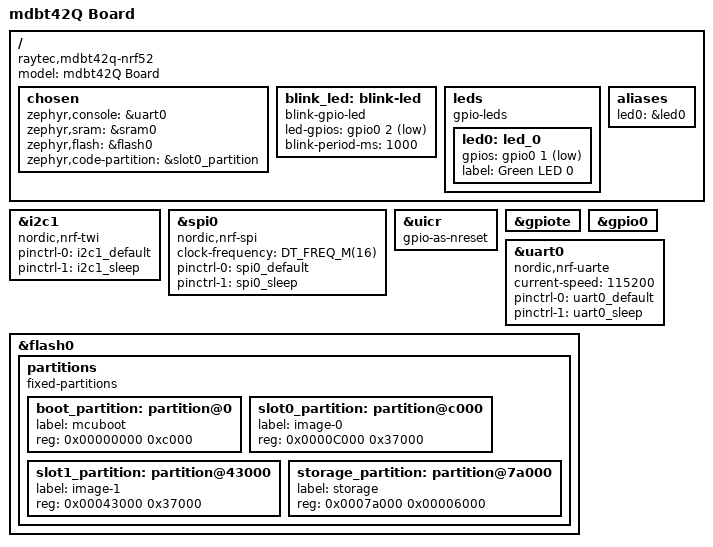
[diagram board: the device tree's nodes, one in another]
/*
 * Copyright (c) 2021 Nordic Semiconductor ASA
 * SPDX-License-Identifier: Apache-2.0
 */

/dts-v1/;
#include <nordic/nrf52832_qfaa.dtsi>
#include "mdbt42q_nrf52-pinctrl.dtsi"
#include <zephyr/dt-bindings/input/input-event-codes.h>

/ {
	model = "mdbt42Q Board";
	compatible = "raytec,mdbt42q-nrf52";

	chosen {
		zephyr,console = &uart0;
		// zephyr,sram = &sram0;
		// zephyr,flash = &flash0;
		zephyr,sram = &sram0;
		zephyr,flash = &flash0;
		zephyr,code-partition = &slot0_partition;
	};


	blink_led: blink-led {
		compatible = "blink-gpio-led";
		led-gpios = <&gpio0 2 GPIO_ACTIVE_LOW>;
		blink-period-ms = <1000>;
	};

	leds {
		compatible = "gpio-leds";
		led0: led_0 {
			gpios = <&gpio0 1 GPIO_ACTIVE_LOW>;
			label = "Green LED 0";
		};
	};

	// arduino_header: connector {
	// 	compatible = "arduino-header-r3";
	// 	#gpio-cells = <2>;
	// 	gpio-map-mask = <0xffffffff 0xffffffc0>;
	// 	gpio-map-pass-thru = <0 0x3f>;
	// 	gpio-map = <0 0 &gpio0 3 0>,	/* A0 */
	// 		   <1 0 &gpio0 4 0>,	/* A1 */
	// 		   <2 0 &gpio0 28 0>,	/* A2 */
	// 		   <3 0 &gpio0 29 0>,	/* A3 */
	// 		   <4 0 &gpio0 30 0>,	/* A4 */
	// 		   <5 0 &gpio0 31 0>,	/* A5 */
	// 		   <6 0 &gpio0 11 0>,	/* D0 */
	// 		   <7 0 &gpio0 12 0>,	/* D1 */
	// 		   <8 0 &gpio0 13 0>,	/* D2 */
	// 		   <9 0 &gpio0 14 0>,	/* D3 */
	// 		   <10 0 &gpio0 15 0>,	/* D4 */
	// 		   <11 0 &gpio0 16 0>,	/* D5 */
	// 		   <12 0 &gpio0 17 0>,	/* D6 */
	// 		   <13 0 &gpio0 18 0>,	/* D7 */
	// 		   <14 0 &gpio0 19 0>,	/* D8 */
	// 		   <15 0 &gpio0 20 0>,	/* D9 */
	// 		   <16 0 &gpio0 22 0>,	/* D10 */
	// 		   <17 0 &gpio0 23 0>,	/* D11 */
	// 		   <18 0 &gpio0 24 0>,	/* D12 */
	// 		   <19 0 &gpio0 25 0>,	/* D13 */
	// 		   <20 0 &gpio0 26 0>,	/* D14 */
	// 		   <21 0 &gpio0 27 0>;	/* D15 */
	// };

	aliases {
		led0 = &led0;
	};

};

arduino_i2c: &i2c1 {
	compatible = "nordic,nrf-twi";
	status = "okay";
	pinctrl-0 = <&i2c1_default>;
	pinctrl-1 = <&i2c1_sleep>;
	pinctrl-names = "default", "sleep";
};

arduino_spi: &spi0 {
	compatible = "nordic,nrf-spi";
	/* Cannot be used together with i2c0. */
	status = "okay";
	/* default freq 3M */
	clock-frequency = <DT_FREQ_M(16)>;
	pinctrl-0 = <&spi0_default>;
	pinctrl-1 = <&spi0_sleep>;
	pinctrl-names = "default", "sleep";
};

&uicr {
	gpio-as-nreset;
};

&gpiote {
	status = "okay";
};

&gpio0 {
	status = "okay";
};

&uart0 {
	compatible = "nordic,nrf-uarte";
	status = "okay";

	current-speed = <115200>;
	pinctrl-0 = <&uart0_default>;
	pinctrl-1 = <&uart0_sleep>;
	pinctrl-names = "default", "sleep";
};

&flash0 {

	partitions {
		compatible = "fixed-partitions";
		#address-cells = <1>;
		#size-cells = <1>;

		boot_partition: partition@0 {
			label = "mcuboot";
			reg = <0x00000000 0xc000>;
		};
		slot0_partition: partition@c000 {
			label = "image-0";
			reg = <0x0000C000 0x37000>;
		};
		slot1_partition: partition@43000 {
			label = "image-1";
			reg = <0x00043000 0x37000>;
		};
		storage_partition: partition@7a000 {
			label = "storage";
			reg = <0x0007a000 0x00006000>;
		};
	};
};

// &flash0 {

// 	partitions {
// 		compatible = "fixed-partitions";
// 		#address-cells = <1>;
// 		#size-cells = <1>;

// 		boot_partition: partition@0 {
// 			label = "mcuboot";
// 			reg = <0x0 0xc000>;
// 		};
// 		slot0_partition: partition@c000 {
// 			label = "image-0";
// 			reg = <0xc000 0x32000>;
// 		};
// 		slot1_partition: partition@3e000 {
// 			label = "image-1";
// 			reg = <0x3e000 0x32000>;
// 		};
// 		scratch_partition: partition@70000 {
// 			label = "image-scratch";
// 			reg = <0x70000 0xa000>;
// 		};
// 		storage_partition: partition@7a000 {
// 			label = "storage";
// 			reg = <0x7a000 0x6000>;
// 		};
// 	};
// };
